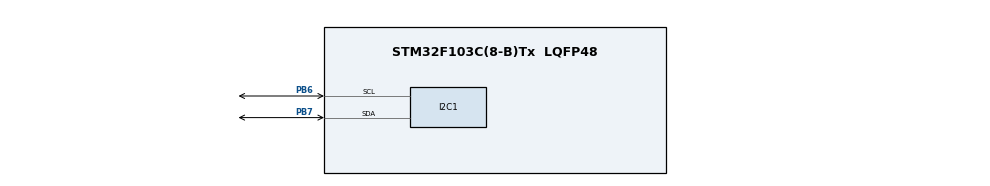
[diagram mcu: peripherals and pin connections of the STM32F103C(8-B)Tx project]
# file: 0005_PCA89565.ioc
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Mcu.Family=STM32F1
Mcu.Name=STM32F103C(8-B)Tx
Mcu.Package=LQFP48
NVIC.PriorityGroup=NVIC_PRIORITYGROUP_4
PA13.Mode=Serial_Wire
PA13.Signal=SYS_JTMS-SWDIO
PA14.Mode=Serial_Wire
PA14.Signal=SYS_JTCK-SWCLK
PB6.Mode=I2C
PB6.Signal=I2C1_SCL
PB7.Mode=I2C
PB7.Signal=I2C1_SDA
ProjectManager.HeapSize=0x200
ProjectManager.StackSize=0x400
ProjectManager.TargetToolchain=STM32CubeIDE
RCC.APB1Freq_Value=8000000
RCC.APB2Freq_Value=8000000
board=custom

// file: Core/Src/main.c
/* USER CODE BEGIN Header */
/**
  ******************************************************************************
  * @file           : main.c
  * @brief          : Main program body
  ******************************************************************************
  * @attention
  *
  * Copyright (c) 2025 STMicroelectronics.
  * All rights reserved.
  *
  * This software is licensed under terms that can be found in the LICENSE file
  * in the root directory of this software component.
  * If no LICENSE file comes with this software, it is provided AS-IS.
  *
  ******************************************************************************
  */
/* USER CODE END Header */
#include "main.h"

I2C_HandleTypeDef hi2c1;

void SystemClock_Config(void);
static void MX_GPIO_Init(void);
static void MX_I2C1_Init(void);

/* USER CODE BEGIN 0 */
#define PCA9685_ADDRESS 0x40
// Datasheet link --> https://cdn-shop.adafruit.com/datasheets/PCA9685.pdf
#define PCA9685_MODE1         0x0         // as in the datasheet page no 10/52
#define PCA9685_PRE_SCALE     0xFE        // as in the datasheet page no 13/52
#define PCA9685_LED0_ON_L     0x6         // as in the datasheet page no 10/52
#define PCA9685_MODE1_SLEEP_BIT      4    // as in the datasheet page no 14/52
#define PCA9685_MODE1_AI_BIT         5    // as in the datasheet page no 14/52
#define PCA9685_MODE1_RESTART_BIT    7    // as in the datasheet page no 14/52

void PCA9685_SetBit(uint8_t Register, uint8_t Bit, uint8_t Value)
{
  uint8_t readValue;
  // Read all 8 bits and set only one bit to 0/1 and write all 8 bits back
  //HAL_I2C_Mem_Read(&hi2c1, PCA9685_ADDRESS, Register, 1, &readValue, 1, 10);
  //GEMINI
  HAL_I2C_Mem_Read(&hi2c1, PCA9685_ADDRESS << 1, Register, 1, &readValue, 1, 10);
  if (Value == 0) readValue &= ~(1 << Bit);
  else readValue |= (1 << Bit);
  //HAL_I2C_Mem_Write(&hi2c1, PCA9685_ADDRESS, Register, 1, &readValue, 1, 10);
  //GEMINI
  HAL_I2C_Mem_Write(&hi2c1, PCA9685_ADDRESS << 1, Register, 1, &readValue, 1, 10);
  HAL_Delay(1);
}

void PCA9685_SetPWMFrequency(uint16_t frequency)
{
  uint8_t prescale;
  if(frequency >= 1526) prescale = 0x03;
  else if(frequency <= 24) prescale = 0xFF;
  //  internal 25 MHz oscillator as in the datasheet page no 1/52
  else prescale = 25000000 / (4096 * frequency);
  // prescale changes 3 to 255 for 1526Hz to 24Hz as in the datasheet page no 1/52
  PCA9685_SetBit(PCA9685_MODE1, PCA9685_MODE1_SLEEP_BIT, 1);
  //HAL_I2C_Mem_Write(&hi2c1, PCA9685_ADDRESS, PCA9685_PRE_SCALE, 1, &prescale, 1, 10);
  //GEMINI
  HAL_I2C_Mem_Write(&hi2c1, PCA9685_ADDRESS << 1, PCA9685_PRE_SCALE, 1, &prescale, 1, 10);

  PCA9685_SetBit(PCA9685_MODE1, PCA9685_MODE1_SLEEP_BIT, 0);
  PCA9685_SetBit(PCA9685_MODE1, PCA9685_MODE1_RESTART_BIT, 1);
}

void PCA9685_Init(uint16_t frequency)
{
  PCA9685_SetPWMFrequency(frequency); // 50 Hz for servo
  PCA9685_SetBit(PCA9685_MODE1, PCA9685_MODE1_AI_BIT, 1);
}

void PCA9685_SetPWM(uint8_t Channel, uint16_t OnTime, uint16_t OffTime)
{
  uint8_t registerAddress;
  uint8_t pwm[4];
  registerAddress = PCA9685_LED0_ON_L + (4 * Channel);
  // See example 1 in the datasheet page no 18/52
  pwm[0] = OnTime & 0xFF;
  pwm[1] = OnTime>>8;
  pwm[2] = OffTime & 0xFF;
  pwm[3] = OffTime>>8;
  //HAL_I2C_Mem_Write(&hi2c1, PCA9685_ADDRESS, registerAddress, 1, pwm, 4, 10);
  //GEMINI
  HAL_I2C_Mem_Write(&hi2c1, PCA9685_ADDRESS << 1, registerAddress, 1, pwm, 4, 10);
}

void PCA9685_SetServoAngle(uint8_t Channel, float Angle)
{
  float Value;
  // 50 Hz servo then 4095 Value --> 20 milliseconds
  // 0 degree --> 0.5 ms(102.4 Value) and 180 degree --> 2.5 ms(511.9 Value)
  //GEMINI: 0 degree --> (90 Value) and 180 degree --> (350 Value)
  Value = (Angle * (350 - 90) / 180.0) + 90;
  PCA9685_SetPWM(Channel, 0, (uint16_t)Value);
}
/* USER CODE END 0 */

int main(void){

  /* MCU Configuration--------------------------------------------------------*/

  /* Reset of all peripherals, Initializes the Flash interface and the Systick. */
  HAL_Init();

  /* Configure the system clock */
  SystemClock_Config();

  /* Initialize all configured peripherals */
  MX_GPIO_Init();
  MX_I2C1_Init();
  /* USER CODE BEGIN 2 */
  PCA9685_Init(50); // 50Hz for servo
  /* USER CODE END 2 */

  /* Infinite loop */
  /* USER CODE BEGIN WHILE */
  while (1)
  {
	  PCA9685_SetServoAngle(6, 0);
	  HAL_Delay(2000);
	  PCA9685_SetServoAngle(6, 90);
	  HAL_Delay(2000);
	  PCA9685_SetServoAngle(6, 180);
	  HAL_Delay(2000);

//	  PCA9685_SetPWM(6, 0, 360);
//	  HAL_Delay(2000);
//	  PCA9685_SetPWM(6, 0, 250);
//	  HAL_Delay(2000);
	  /* USER CODE END WHILE */

  }
}

void SystemClock_Config(void)
{
  RCC_OscInitTypeDef RCC_OscInitStruct = {0};
  RCC_ClkInitTypeDef RCC_ClkInitStruct = {0};

  /** Initializes the RCC Oscillators according to the specified parameters
  * in the RCC_OscInitTypeDef structure.
  */
  RCC_OscInitStruct.OscillatorType = RCC_OSCILLATORTYPE_HSI;
  RCC_OscInitStruct.HSIState = RCC_HSI_ON;
  RCC_OscInitStruct.HSICalibrationValue = RCC_HSICALIBRATION_DEFAULT;
  RCC_OscInitStruct.PLL.PLLState = RCC_PLL_NONE;
  if (HAL_RCC_OscConfig(&RCC_OscInitStruct) != HAL_OK)
  {
    Error_Handler();
  }

  /** Initializes the CPU, AHB and APB buses clocks
  */
  RCC_ClkInitStruct.ClockType = RCC_CLOCKTYPE_HCLK|RCC_CLOCKTYPE_SYSCLK
                              |RCC_CLOCKTYPE_PCLK1|RCC_CLOCKTYPE_PCLK2;
  RCC_ClkInitStruct.SYSCLKSource = RCC_SYSCLKSOURCE_HSI;
  RCC_ClkInitStruct.AHBCLKDivider = RCC_SYSCLK_DIV1;
  RCC_ClkInitStruct.APB1CLKDivider = RCC_HCLK_DIV1;
  RCC_ClkInitStruct.APB2CLKDivider = RCC_HCLK_DIV1;

  if (HAL_RCC_ClockConfig(&RCC_ClkInitStruct, FLASH_LATENCY_0) != HAL_OK)
  {
    Error_Handler();
  }
}

static void MX_I2C1_Init(void)
{

  hi2c1.Instance = I2C1;
  hi2c1.Init.ClockSpeed = 100000;
  hi2c1.Init.DutyCycle = I2C_DUTYCYCLE_2;
  hi2c1.Init.OwnAddress1 = 0;
  hi2c1.Init.AddressingMode = I2C_ADDRESSINGMODE_7BIT;
  hi2c1.Init.DualAddressMode = I2C_DUALADDRESS_DISABLE;
  hi2c1.Init.OwnAddress2 = 0;
  hi2c1.Init.GeneralCallMode = I2C_GENERALCALL_DISABLE;
  hi2c1.Init.NoStretchMode = I2C_NOSTRETCH_DISABLE;
  if (HAL_I2C_Init(&hi2c1) != HAL_OK)
  {
    Error_Handler();
  }

}

static void MX_GPIO_Init(void)
{

  /* GPIO Ports Clock Enable */
  __HAL_RCC_GPIOA_CLK_ENABLE();
  __HAL_RCC_GPIOB_CLK_ENABLE();

}

void Error_Handler(void)
{
  __disable_irq();
  while (1)
  {
  }
}
